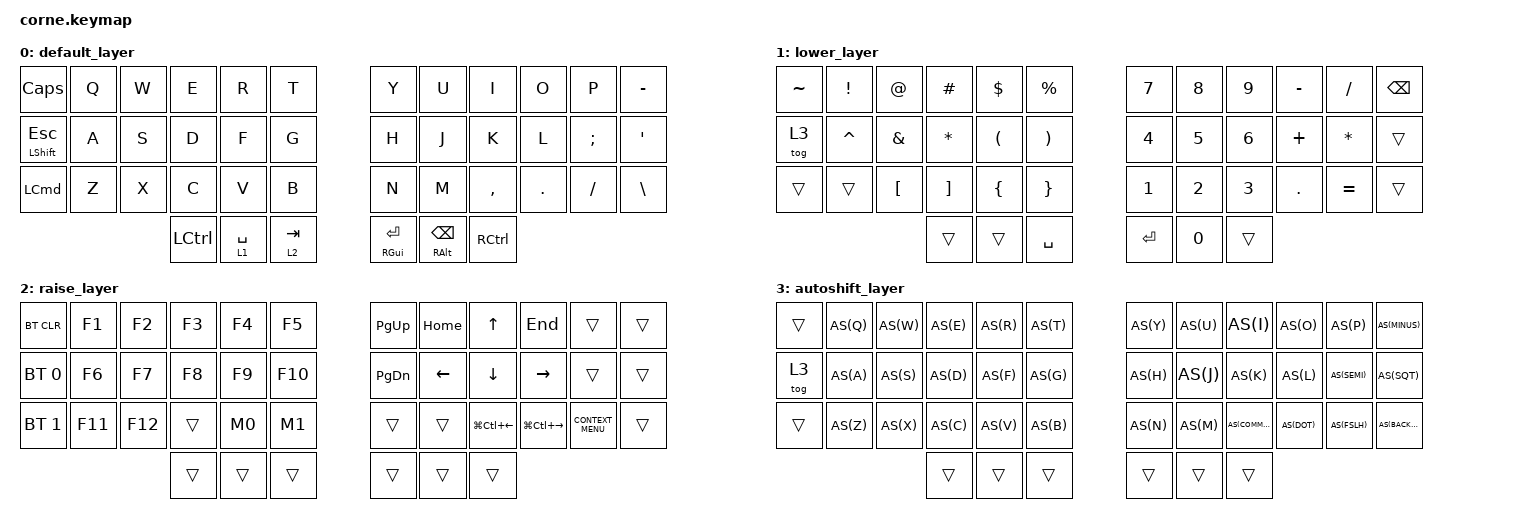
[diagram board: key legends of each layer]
/*
 * Copyright (c) 2020 The ZMK Contributors
 *
 * SPDX-License-Identifier: MIT
 */

#include <behaviors.dtsi>
#include <dt-bindings/zmk/bt.h>
#include <dt-bindings/zmk/keys.h>


#define AS(kc) &as LS(kc) kc

/* Tap then hold behavior tuning for mod-tap / layer-tap keys */
&mt {
    quick-tap-ms = <200>;
};

&lt {
    quick-tap-ms = <200>;
};


/ {
    macros {
        M0: M0 {
            compatible = "zmk,behavior-macro";
            #binding-cells = <0>;
            bindings = <&kp LC(LA(LS(LCMD)))>;
            label = "M0";
        };

        M1: M1 {
            compatible = "zmk,behavior-macro";
            #binding-cells = <0>;
            bindings = <&kp LA(LS(LC(Q)))>;
            label = "M1";
        };
    };

        behaviors {
        as: auto_shift {
            compatible = "zmk,behavior-hold-tap";
            #binding-cells = <2>;
            flavor = "tap-preferred";
            tapping-term-ms = <135>;
            quick-tap-ms = <0>;
            bindings = <&kp>, <&kp>;
            label = "AUTO_SHIFT";
        };
    };

    keymap {
        compatible = "zmk,keymap";

        default_layer {
            // -----------------------------------------------------------------------------------------
            // | CAPS|  Q  |  W  |  E  |  R  |  T  |   |  Y  |  U   |  I  |  O  |  P  |  -   |
            // | ESC |  A  |  S  |  D  |  F  |  G  |   |  H  |  J   |  K  |  L  |  ;  |  '   |
            // | CMD |  Z  |  X  |  C  |  V  |  B  |   |  N  |  M   |  ,  |  .  |  /  | ESC  |
            //                    | Ctl| SPC | Tab |   | ENT | BSP  | Ctl |

            bindings = <
&kp CAPSLOCK      &kp Q  &kp W  &kp E      &kp R        &kp T        &kp Y                &kp U                    &kp I              &kp O    &kp P     &kp MINUS
&mt LSHFT ESCAPE  &kp A  &kp S  &kp D      &kp F        &kp G        &kp H                &kp J                    &kp K              &kp L    &kp SEMI  &kp SQT
&kp LCMD          &kp Z  &kp X  &kp C      &kp V        &kp B        &kp N                &kp M                    &kp COMMA          &kp DOT  &kp FSLH  &kp BACKSLASH
                                &kp LCTRL  &lt 1 SPACE  &lt 2 TAB    &mt RIGHT_GUI ENTER  &mt RIGHT_ALT BACKSPACE  &kp RIGHT_CONTROL
            >;
        };

        lower_layer {
            // -----------------------------------------------------------------------------------------
            // |  ~   |  !  |  @  |  #  |  $  |  %  |   |  7  |  8  |  9  |  -  |  /  | BSPC |
            // | AS_Tg|  ^  |  &  |  *  |  (  |  )  |   |  4  |  5  |  6  |  +  |  *  |      |
            // |      |     |  [  |  ]  |  {  |  }  |   |  1  |  2  |  3  |  .  |  =  |      |
            //                    | Ctl | SPC | Tab |   | ENT |  0  | Ctl |

            bindings = <
&kp TILDE   &kp EXCL   &kp AT            &kp HASH           &kp DOLLAR            &kp PERCENT              &kp N7        &kp N8        &kp N9        &kp MINUS   &kp SLASH  &kp BSPC
&tog 3  &kp CARET  &kp AMPERSAND     &kp ASTRK          &kp LEFT_PARENTHESIS  &kp RIGHT_PARENTHESIS    &kp NUMBER_4  &kp N5        &kp NUMBER_6  &kp PLUS    &kp ASTRK  &trans
&trans      &trans     &kp LEFT_BRACKET  &kp RIGHT_BRACKET  &kp LEFT_BRACE        &kp RIGHT_BRACE          &kp NUMBER_1  &kp NUMBER_2  &kp NUMBER_3  &kp PERIOD  &kp EQUAL  &trans
                                         &trans             &trans                &kp SPACE                &kp RET       &kp N0        &trans
            >;
        };

        raise_layer {
            // -----------------------------------------------------------------------------------------
            // | BTCLR| F1  | F2  | F3  | F4  | F5  |   |PGUP | HM  | UP  | END |     |      |
            // |  BT1 | F6  | F7  | F8  | F9  | F10 |   |PGDWN| LFT | DWN | RGT |     |      |
            // |  BT2 | F11 | F12 |     | M0  | M1  |   |     |     | FSL | FSR | APP |      |
            //                    | Ctl | SPC | Tab |   | ENT | BSP | Ctl |

            bindings = <
&bt BT_CLR    &kp F1   &kp F2   &kp F3  &kp F4  &kp F5     &kp PAGE_UP    &kp HOME  &kp UP_ARROW      &kp END            &trans              &trans
&bt BT_SEL 0  &kp F6   &kp F7   &kp F8  &kp F9  &kp F10    &kp PAGE_DOWN  &kp LEFT  &kp DOWN          &kp RIGHT          &trans              &trans
&bt BT_SEL 1  &kp F11  &kp F12  &trans  &M0     &M1        &trans         &trans    &kp LG(LC(LEFT))  &kp LG(LC(RIGHT))  &kp K_CONTEXT_MENU  &trans
                                &trans  &trans  &trans     &trans         &trans    &trans
            >;
        };

        autoshift_layer {
            // Layer 3: tap = normal key, hold = shifted version
            bindings = <
&trans  AS(Q)      AS(W)      AS(E)      AS(R)      AS(T)      AS(Y)      AS(U)      AS(I)      AS(O)      AS(P)      AS(MINUS)
&tog 3  AS(A)      AS(S)      AS(D)      AS(F)      AS(G)      AS(H)      AS(J)      AS(K)      AS(L)      AS(SEMI)   AS(SQT)
&trans  AS(Z)      AS(X)      AS(C)      AS(V)      AS(B)      AS(N)      AS(M)      AS(COMMA)  AS(DOT)    AS(FSLH)   AS(BACKSLASH)
                   &trans     &trans     &trans     &trans     &trans     &trans
            >;
        };
    };
};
